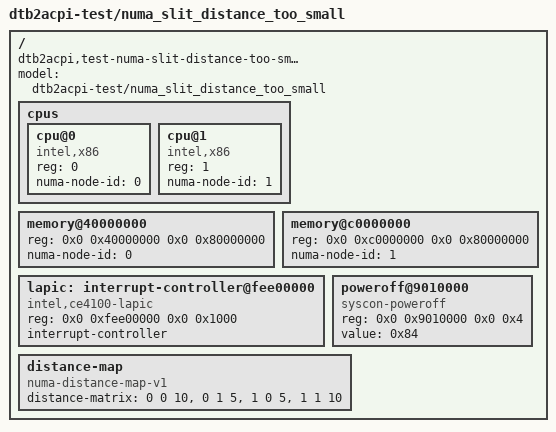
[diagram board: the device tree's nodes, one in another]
/dts-v1/;

/* `distance-matrix` lists an off-diagonal distance < 10. ACPI 6.5
 * §5.2.17 reserves 0..9 (0 also collides with `slit::emit`'s
 * "unwritten" sentinel). Hits the `val_u8 < 10 → malformed` arm
 * for off-diagonals — the existing fixtures cover the diagonal
 * `!= 10` rejection and the > 255 narrowing failure, but not the
 * lower-bound rejection.
 */

/ {
	#address-cells = <2>;
	#size-cells = <2>;
	model = "dtb2acpi-test/numa_slit_distance_too_small";
	compatible = "dtb2acpi,test-numa-slit-distance-too-small";

	cpus {
		#address-cells = <1>;
		#size-cells = <0>;

		cpu@0 {
			device_type = "cpu";
			reg = <0>;
			compatible = "intel,x86";
			numa-node-id = <0>;
		};

		cpu@1 {
			device_type = "cpu";
			reg = <1>;
			compatible = "intel,x86";
			numa-node-id = <1>;
		};
	};

	memory@40000000 {
		device_type = "memory";
		reg = <0x0 0x40000000 0x0 0x80000000>;
		numa-node-id = <0>;
	};

	memory@c0000000 {
		device_type = "memory";
		reg = <0x0 0xc0000000 0x0 0x80000000>;
		numa-node-id = <1>;
	};

		lapic: interrupt-controller@fee00000 {
		compatible = "intel,ce4100-lapic";
		reg = <0x0 0xfee00000 0x0 0x1000>;
		interrupt-controller;
		#interrupt-cells = <2>;
	};
		poweroff@9010000 {
		compatible = "syscon-poweroff";
		reg = <0x0 0x9010000 0x0 0x4>;
		value = <0x84>;
	};

	distance-map {
		compatible = "numa-distance-map-v1";
		/* Off-diagonal value of 5 is below the ACPI-spec
		 * minimum of 10 — must be rejected. */
		distance-matrix = <0 0 10>,
		                  <0 1 5>,
		                  <1 0 5>,
		                  <1 1 10>;
	};
};
